# STM32WB07 register map
File version: 0.4
CPU: CM0+ r0p0, little endian, MPU, no FPU, 2 interrupt priority bits
Registers are 32-bit, read-write, reset 0x0 unless marked. A register's access mark holds for its fields unless they carry their own. Offsets are from the block's base; [hi:lo] are bit positions; {n}, {i} and the like mark numbered series.

## FLASH_CTRL — 4kb addressable space
Base 0x40001000
0x00 COMMAND
  [7:0] COMMAND — Macro commands for flash operations (may require DATA0...DATA3 to be set): - 0x11 : ERASE - 0x22 : MASSERASE - 0x33 : WRITE - 0x44 : MASSWRITE - 0x55 : MASSREAD - 0x66 : IFRERASE - 0x77 : IFRWRITE - 0x88 : IFRMASSWRITE - 0x99 : IFRMASSREAD - 0xAA : SLEEP - 0xBB : WAKEUP - 0xCC : BURSTWRITE - 0xDD : IFRBURSTWRITE - 0xEE : OTPWRITE - 0xFF : KEYWRITE
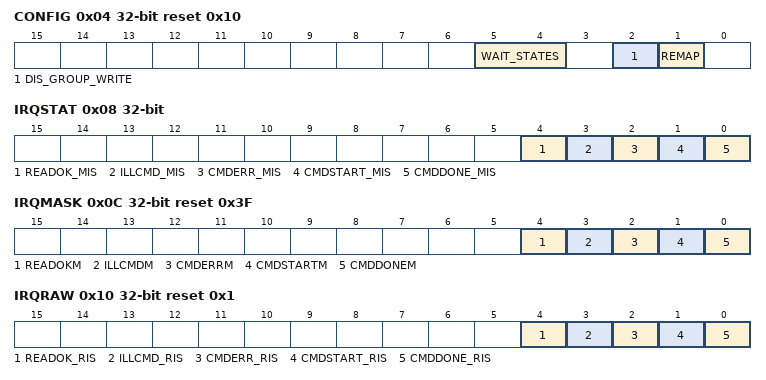
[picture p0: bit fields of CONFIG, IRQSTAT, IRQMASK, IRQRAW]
0x04 CONFIG reset 0x10
  [5:4] WAIT_STATES — Number of wait states to be inserted on Flash read (AHB accesses)
  [2] DIS_GROUP_WRITE — Burst write Control: - 0 : burst write allowed - 1 : burst write forbidden
  [1] REMAP — Bit to redirect boot area on SRAM0.
0x08 IRQSTAT
  [4] READOK_MIS — Mass read OK masked interrupt status.
  [3] ILLCMD_MIS — Illegal command masked interrupt status
  [2] CMDERR_MIS — Command error masked interrupt status.
  [1] CMDSTART_MIS — Command started masked interrupt status.
  [0] CMDDONE_MIS — Command done masked interrupt status.
0x0C IRQMASK reset 0x3F
  [4] READOKM — Mass read OK mask.
  [3] ILLCMDM — Illegal command mask.
  [2] CMDERRM — Command error mask.
  [1] CMDSTARTM — Command started mask.
  [0] CMDDONEM — Command done mask
0x10 IRQRAW reset 0x1
  [4] READOK_RIS — Mass read OK raw/unmasked interrupt status
  [3] ILLCMD_RIS — Illegal command raw/unmasked interrupt status.
  [2] CMDERR_RIS — Command error raw/unmasked interrupt status
  [1] CMDSTART_RIS — Command started raw/unmasked interrupt status. This bit is set once the requested command execution has started.
  [0] CMDDONE_RIS — Command done raw/unmasked interrupt status. This it is set once the requested command execution is completed. Cleared by writing 1.
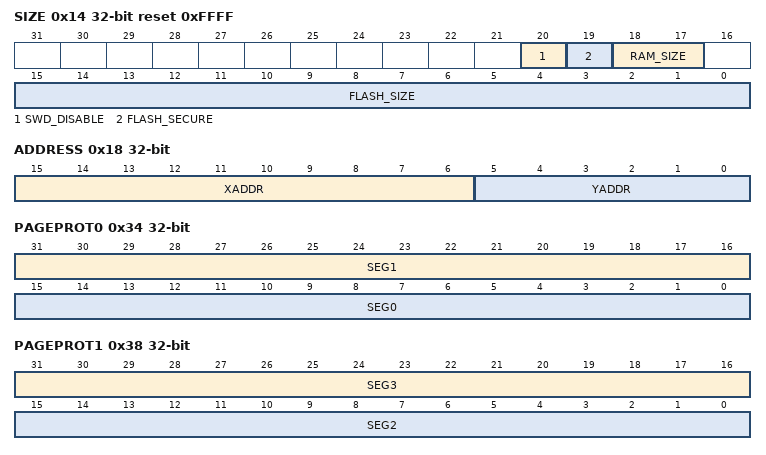
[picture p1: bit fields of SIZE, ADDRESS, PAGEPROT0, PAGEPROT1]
0x14 SIZE ro reset 0xFFFF
  [20] SWD_DISABLE — Flash+SWD protection: 0: No SWD protection (refer to FLASH_SECURE) 1: Flash and SWD protected
  [19] FLASH_SECURE — Flash memory protection (0: no key present, 1: key present)
  [18:17] RAM_SIZE — RAM memory size selection: - 00 : 32kb - 01 : 32kb - 10 : 48kb - 11 : 64kb
  [15:0] FLASH_SIZE — Maximum valid address for flash memory: - 00 : 0x0BFFF (192kb) - 01 : 0x0FFFF (256kb) - 10 : 0x17FFF (384kb) - 11 : 0x1FFFF (512kb)
0x18 ADDRESS
  [15:6] XADDR — Flash row address offset to be used with some COMMAND
  [5:0] YADDR — Flash column address offset to be used with some COMMAND
0x24 LFSRVAL ro reset 0xFFFFFFFF
  [31:0] LFSRVAL — Flash read data CRC signature
0x34 PAGEPROT0
  [31:16] SEG1 — Second segment definition. See SEG0 description for details on SEG1[31:16] content
  [15:0] SEG0 — First segment definition.
0x38 PAGEPROT1
  [31:16] SEG3 — Fourth segment definition. See PAGEPROT0 SEG0 description for details on SEG3[15:0] content.
  [15:0] SEG2 — Third segment definition. See PAGEPROT0 SEG0 description for details on SEG2[15:0] content
0x40 DATA0 reset 0xFFFFFFFF
  [31:0] DATA0 — Value to be used as DATA for any COMMAND of type WRITE and compare value for MASSREAD
{0x40+4i} DATA{i} reset 0xFFFFFFFF (i=1..3)
  [31:0] DATA{i} — Value to be used as DATA for any COMMAND of type WRITE

## RNG
Base 0x48600000
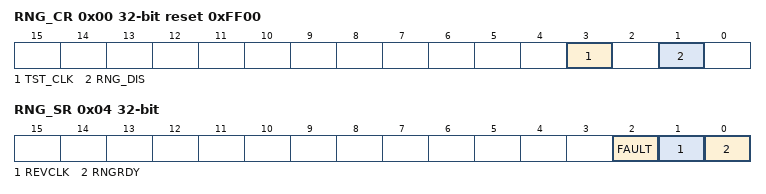
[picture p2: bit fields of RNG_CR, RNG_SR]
0x00 RNG_CR reset 0xFF00
  [3] TST_CLK — Reset reveal clock error flags when writing a '1' without resetting the whole TRNG. When writing a 1, the value remains until it is seen by RNG core clock domain after resynchronization. Then it is automatically reset.
    0=no reset; 1=reset revclk flag
  [1] RNG_DIS — This bit enables or disables the random number generator. 0: RNG is enabled (default) 1: RNG is disabled. The internal free-running oscillators are put in power-down mode and the RNG clock is stopped at the input of the block.
    0=The RNG core is enabled; 1=The RNG core is disabled
0x04 RNG_SR ro
  [2] FAULT — Fault reveal bit.
    0=Internal clock for RNG clock is present; 1=Internal RNG clock is not present
  [1] REVCLK — RNGCLK clock reveal bit.
    0=At least one oscillator is ON; 1=All oscillators are down
  [0] RNGRDY — New random value ready
    0=Normal operation; 1=RNG is disabled
0x08 RNG_VAL ro
  [15:0] RND_VAL — Random value
